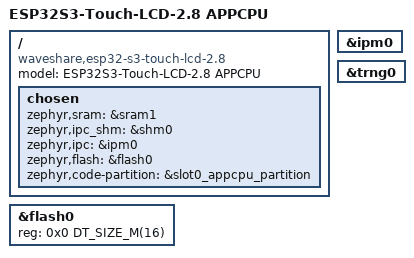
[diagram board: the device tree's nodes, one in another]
/*
 * Copyright (c) 2025 Harry Jiang
 * SPDX-License-Identifier: Apache-2.0
 */

/dts-v1/;
#include <espressif/esp32s3/esp32s3_r8.dtsi>
#include <espressif/partitions_0x0_amp_16M.dtsi>

/ {
	model = "ESP32S3-Touch-LCD-2.8 APPCPU";
	compatible = "waveshare,esp32-s3-touch-lcd-2.8";

	chosen {
		zephyr,sram = &sram1;
		zephyr,ipc_shm = &shm0;
		zephyr,ipc = &ipm0;
		zephyr,flash = &flash0;
		zephyr,code-partition = &slot0_appcpu_partition;
	};
}; 

&flash0 {
	reg = <0x0 DT_SIZE_M(16)>;
};

&ipm0 {
	status = "okay";
};

&trng0 {
	status = "okay";
};
